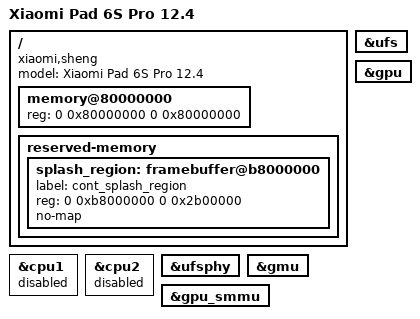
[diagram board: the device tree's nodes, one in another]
// SPDX-License-Identifier: BSD-3-Clause
/dts-v1/;
/include/ "sm8550.dtsi"

/ {
    model = "Xiaomi Pad 6S Pro 12.4";
    compatible = "xiaomi,sheng", "qcom,sm8550";

    memory@80000000 {
        device_type = "memory";
        reg = <0 0x80000000 0 0x80000000>;
    };

    reserved-memory {
        #address-cells = <2>;
        #size-cells = <2>;
        ranges;
        splash_region: framebuffer@b8000000 {
            label = "cont_splash_region";
            reg = <0 0xb8000000 0 0x2b00000>;
            no-map;
        };
    };
};

&cpu1 { status = "disabled"; };
&cpu2 { status = "disabled"; };
&ufs { status = "okay"; };
&ufsphy { status = "okay"; };
&gpu { status = "okay"; };
&gmu { status = "okay"; };
&gpu_smmu { status = "okay"; };
